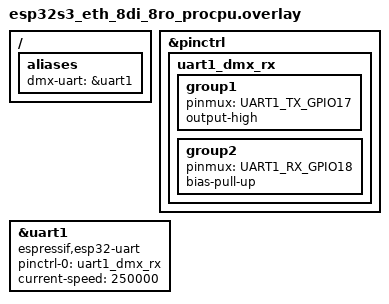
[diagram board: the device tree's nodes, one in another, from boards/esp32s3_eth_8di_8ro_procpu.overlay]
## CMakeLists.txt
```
# SPDX-License-Identifier: Apache-2.0
#
# dmx-fixture — DMX512 relay actuator

cmake_minimum_required(VERSION 3.20.0)

SET(CMAKE_C_USE_RESPONSE_FILE_FOR_OBJECTS 1)
SET(CMAKE_CXX_USE_RESPONSE_FILE_FOR_OBJECTS 1)
SET(CMAKE_C_RESPONSE_FILE_LINK_FLAG "@")
SET(CMAKE_CXX_RESPONSE_FILE_LINK_FLAG "@")
SET(CMAKE_NINJA_FORCE_RESPONSE_FILE 1 CACHE INTERNAL "")

find_package(Zephyr REQUIRED HINTS $ENV{ZEPHYR_BASE})
project(dmx_fixture)

target_sources(app PRIVATE src/main.c)

add_subdirectory(../dmx-z ${CMAKE_BINARY_DIR}/dmx-z)
add_subdirectory(src/modules/relay)
```

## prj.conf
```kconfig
# SPDX-License-Identifier: Apache-2.0
#
# dmx-fixture — DMX512 relay actuator for ESP32-S3 Waveshare POE ETH 8DI 8RO.
# Receives DMX slots from the RS485 bus and controls 8 relays via PCA9538.

CONFIG_HEAP_MEM_POOL_SIZE=65000
CONFIG_PINCTRL=y

# Peripherals
CONFIG_GPIO=y
CONFIG_I2C=y
CONFIG_I2C_ESP32=y
CONFIG_GPIO_PCA953X=y

# Shell / console
CONFIG_SERIAL=y
CONFIG_CONSOLE=y
CONFIG_UART_CONSOLE=y
CONFIG_SHELL=y
CONFIG_SHELL_BACKEND_SERIAL=y
CONFIG_UART_USE_RUNTIME_CONFIGURE=y
CONFIG_UART_LINE_CTRL=y

# Logging
CONFIG_LOG=y

# dmx-z driver (RX only)
CONFIG_DMX_Z=y
CONFIG_DMX_TX=n
CONFIG_DMX_RX=y
CONFIG_DMX_UART_NUM=1
CONFIG_DMX_TXD_INVERT=n
CONFIG_DMX_FIXTURE_START_ADDR=19

# Zbus
CONFIG_ZBUS=y

CONFIG_MAIN_STACK_SIZE=4096
CONFIG_SHELL_STACK_SIZE=4096
CONFIG_LOG_PROCESS_THREAD_STACK_SIZE=2048
```

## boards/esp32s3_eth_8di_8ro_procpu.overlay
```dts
/*
 * Copyright (c) 2026
 * SPDX-License-Identifier: Apache-2.0
 *
 * Board overlay for DMX fixture — ESP32-S3 Waveshare POE ETH 8DI 8RO.
 *
 * UART1 RX (GPIO18) receives the DMX512 stream from the RS485 bus.
 * TX (GPIO17) is kept idle-high so the auto-DE transceiver stays in
 * receive mode.  The PCA9538 GPIO expander drives 8 relay outputs.
 */

#include <dt-bindings/pinctrl/esp32s3-pinctrl.h>
#include <zephyr/dt-bindings/pinctrl/esp-pinctrl-common.h>
#include <zephyr/dt-bindings/pinctrl/esp32s3-gpio-sigmap.h>
#include <zephyr/dt-bindings/pwm/pwm.h>

&pinctrl {
	uart1_dmx_rx: uart1_dmx_rx {
		group1 {
			pinmux = <UART1_TX_GPIO17>;
			output-high;  /* keep transceiver in RX mode */
		};
		group2 {
			pinmux = <UART1_RX_GPIO18>;
			bias-pull-up;
		};
	};
};

/ {
	aliases {
		dmx-uart = &uart1;
	};
};

&uart1 {
	status = "okay";
	compatible = "espressif,esp32-uart";
	pinctrl-0 = <&uart1_dmx_rx>;
	pinctrl-names = "default";
	current-speed = <250000>;
};
```

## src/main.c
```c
/*
 * SPDX-License-Identifier: Apache-2.0
 *
 * dmx-fixture — DMX512 relay actuator for ESP32-S3 8DI 8RO.
 *
 * Receives DMX512 slots from the RS485 bus and controls 8 relays
 * via a PCA9538 GPIO expander.  The DMX start address is configured
 * through CONFIG_DMX_FIXTURE_START_ADDR (Kconfig / prj.conf).
 */

#include <zephyr/kernel.h>
#include <zephyr/device.h>
#include <zephyr/drivers/gpio.h>
#include <zephyr/logging/log.h>

#include <dmx_z.h>

#include "modules/relay/relay_fixture.h"

LOG_MODULE_REGISTER(main, LOG_LEVEL_INF);

#define USB_SERIAL_NODE DT_ALIAS(usb_serial)

int main(void)
{
	const struct device *serial = DEVICE_DT_GET(USB_SERIAL_NODE);

	if (!device_is_ready(serial)) {
		LOG_ERR("USB serial not ready");
		return 0;
	}
	LOG_INF("USB serial ready");

	/*
	 * Initialise the relay fixture first: it drives the PCA9538 over
	 * I²C.  The DMX RX polling thread is started afterwards so that its
	 * UART register access cannot interfere with the I²C transactions
	 * performed during init.
	 */
	int ret = relay_fixture_init(CONFIG_DMX_FIXTURE_START_ADDR);
	if (ret != 0) {
		LOG_ERR("relay_fixture_init failed: %d", ret);
		return 0;
	}

	ret = dmx_rx_init();
	if (ret != 0) {
		LOG_ERR("dmx_rx_init failed: %d", ret);
		return 0;
	}

	LOG_INF("dmx-fixture running");
	return 0;
}
```
